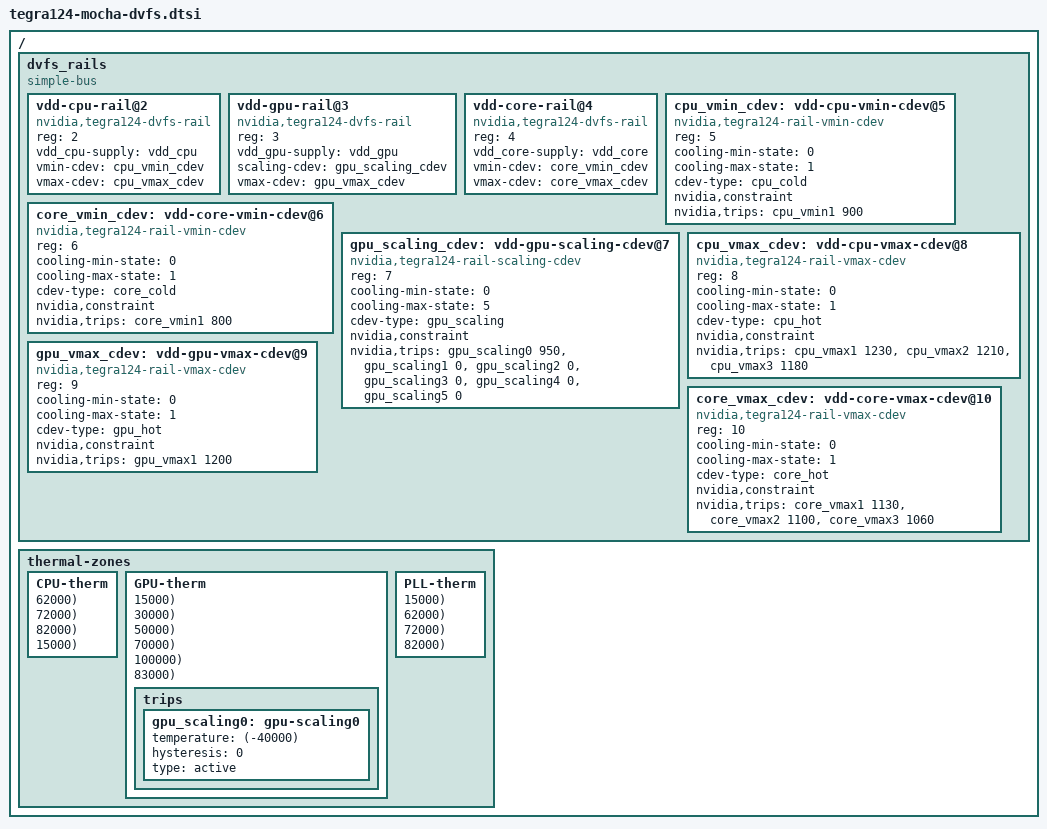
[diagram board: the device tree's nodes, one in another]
/*
 * Copyright (c) 2014-2015 NVIDIA CORPORATION. All rights reserved.
 *
 * This software is licensed under the terms of the GNU General Public
 * License version 2, as published by the Free Software Foundation, and
 * may be copied, distributed, and modified under those terms.
 *
 * This program is distributed in the hope that it will be useful,
 * but WITHOUT ANY WARRANTY; without even the implied warranty of
 * MERCHANTABILITY or FITNESS FOR A PARTICULAR PURPOSE.  See the
 * GNU General Public License for more details.
 *
 */

#define SET_MAP_TRIP(tdomain, cdomain, vtype, num, temp)		\
	trips {								\
		tdomain##_##vtype##num: tdomain-vtype##num {		\
			temperature = <temp>;				\
			hysteresis = <1000>;				\
			type = "active";				\
		};							\
	};								\
	cooling-maps {							\
		tdomain-vtype-map##num {				\
			trip = <&tdomain##_##vtype##num>;		\
			cooling-device = <&cdomain##_##vtype##_cdev num num>; \
		};							\
	}

/ {
	dvfs_rails {

		vdd-cpu-rail@2 {
			status = "okay";
			reg = <2>;
			compatible = "nvidia,tegra124-dvfs-rail";
			vdd_cpu-supply = <&vdd_cpu>;
			vmin-cdev = <&cpu_vmin_cdev>;
			vmax-cdev = <&cpu_vmax_cdev>;
		};

		vdd-gpu-rail@3 {
			status = "okay";
			reg = <3>;
			compatible = "nvidia,tegra124-dvfs-rail";
			vdd_gpu-supply = <&vdd_gpu>;
			scaling-cdev = <&gpu_scaling_cdev>;
			vmax-cdev = <&gpu_vmax_cdev>;
		};

		vdd-core-rail@4 {
			status = "okay";
			reg = <4>;
			compatible = "nvidia,tegra124-dvfs-rail";
			vdd_core-supply = <&vdd_core>;
			vmin-cdev = <&core_vmin_cdev>;
			vmax-cdev = <&core_vmax_cdev>;
		};
	};
};

/ {
	dvfs_rails {
		compatible = "simple-bus";
		#address-cells = <1>;
		#size-cells = <0>;

		cpu_vmin_cdev: vdd-cpu-vmin-cdev@5 {
			status = "okay";
			reg = <5>;
			cooling-min-state = <0>;
			cooling-max-state = <1>;
			#cooling-cells = <2>;
			compatible = "nvidia,tegra124-rail-vmin-cdev";
			cdev-type = "cpu_cold";
			nvidia,constraint;
			nvidia,trips = <&cpu_vmin1 900>;
		};

		core_vmin_cdev: vdd-core-vmin-cdev@6 {
			status = "okay";
			reg = <6>;
			cooling-min-state = <0>;
			cooling-max-state = <1>;
			#cooling-cells = <2>;
			compatible = "nvidia,tegra124-rail-vmin-cdev";
			cdev-type = "core_cold";
			nvidia,constraint;
			nvidia,trips = <&core_vmin1 800>;
		};

		gpu_scaling_cdev: vdd-gpu-scaling-cdev@7 {
			status = "okay";
			reg = <7>;
			cooling-min-state = <0>;
			cooling-max-state = <5>;
			#cooling-cells = <2>;
			compatible = "nvidia,tegra124-rail-scaling-cdev";
			cdev-type = "gpu_scaling";
			nvidia,constraint;
			nvidia,trips = <&gpu_scaling0 950 &gpu_scaling1 0
					&gpu_scaling2 0 &gpu_scaling3 0
					&gpu_scaling4 0 &gpu_scaling5 0>;
		};

		cpu_vmax_cdev: vdd-cpu-vmax-cdev@8 {
			status = "okay";
			reg = <8>;
			cooling-min-state = <0>;
			cooling-max-state = <1>;
			#cooling-cells = <2>;
			compatible = "nvidia,tegra124-rail-vmax-cdev";
			cdev-type = "cpu_hot";
			nvidia,constraint;
			nvidia,trips = <&cpu_vmax1 1230 &cpu_vmax2 1210 &cpu_vmax3 1180>;
		};

		gpu_vmax_cdev: vdd-gpu-vmax-cdev@9 {
			status = "okay";
			reg = <9>;
			cooling-min-state = <0>;
			cooling-max-state = <1>;
			#cooling-cells = <2>;
			compatible = "nvidia,tegra124-rail-vmax-cdev";
			cdev-type = "gpu_hot";
			nvidia,constraint;
			nvidia,trips = <&gpu_vmax1 1200>;
		};

		core_vmax_cdev: vdd-core-vmax-cdev@10 {
			status = "okay";
			reg = <10>;
			cooling-min-state = <0>;
			cooling-max-state = <1>;
			#cooling-cells = <2>;
			compatible = "nvidia,tegra124-rail-vmax-cdev";
			cdev-type = "core_hot";
			nvidia,constraint;
			nvidia,trips = <&core_vmax1 1130 &core_vmax2 1100 &core_vmax3 1060>;
		};
	};

	thermal-zones {
		CPU-therm {
			SET_MAP_TRIP(cpu, cpu, vmax, 1, 62000);
			SET_MAP_TRIP(cpu, cpu, vmax, 2, 72000);
			SET_MAP_TRIP(cpu, cpu, vmax, 3, 82000);
			SET_MAP_TRIP(cpu, cpu, vmin, 1, 15000);
		};
		GPU-therm {
			trips {
				/* Reference only trip, not mapped */
				gpu_scaling0: gpu-scaling0 {
					temperature = <(-40000)>;
					hysteresis = <0>;
					type = "active";
				};
			};
			SET_MAP_TRIP(gpu, gpu, scaling, 1, 15000);
			SET_MAP_TRIP(gpu, gpu, scaling, 2, 30000);
			SET_MAP_TRIP(gpu, gpu, scaling, 3, 50000);
			SET_MAP_TRIP(gpu, gpu, scaling, 4, 70000);
			SET_MAP_TRIP(gpu, gpu, scaling, 5, 100000);
			SET_MAP_TRIP(gpu, gpu, vmax, 1, 83000);
		};
		PLL-therm {
			SET_MAP_TRIP(core, core, vmin, 1, 15000);
			SET_MAP_TRIP(core, core, vmax, 1, 62000);
			SET_MAP_TRIP(core, core, vmax, 2, 72000);
			SET_MAP_TRIP(core, core, vmax, 3, 82000);
		};
	};
};
